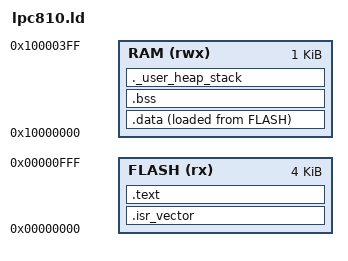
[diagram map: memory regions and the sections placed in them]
MEMORY
{
    FLASH (rx)  : ORIGIN = 0x00000000, LENGTH = 4K
    RAM   (rwx) : ORIGIN = 0x10000000, LENGTH = 1K
}

ENTRY(Reset_Handler)

SECTIONS
{
    .isr_vector :
    {
        KEEP(*(.isr_vector))
    } > FLASH

    .text :
    {
        *(.text*)
        *(.rodata*)
        . = ALIGN(4); /* _sidata (below) must be word-aligned: the
                          startup .data-copy loop uses ldmia, which
                          HardFaults on Cortex-M0+ if its source address
                          isn't 4-byte aligned. Without this, alignment
                          depends on .text+.rodata's total size landing
                          on a lucky boundary by accident. */
    } > FLASH

    _sidata = LOADADDR(.data);

    .data :
    {
        _sdata = .;
        *(.data*)
        _edata = .;
    } > RAM AT> FLASH

    .bss :
    {
        _sbss = .;
        *(.bss*)
        *(COMMON)
        _ebss = .;
    } > RAM

    ._user_heap_stack :
    {
        . = ALIGN(8);
        . = . + 256; /* minimal stack reservation for this bare-metal loop */
        . = ALIGN(8);
    } > RAM

    _estack = ORIGIN(RAM) + LENGTH(RAM);
}
